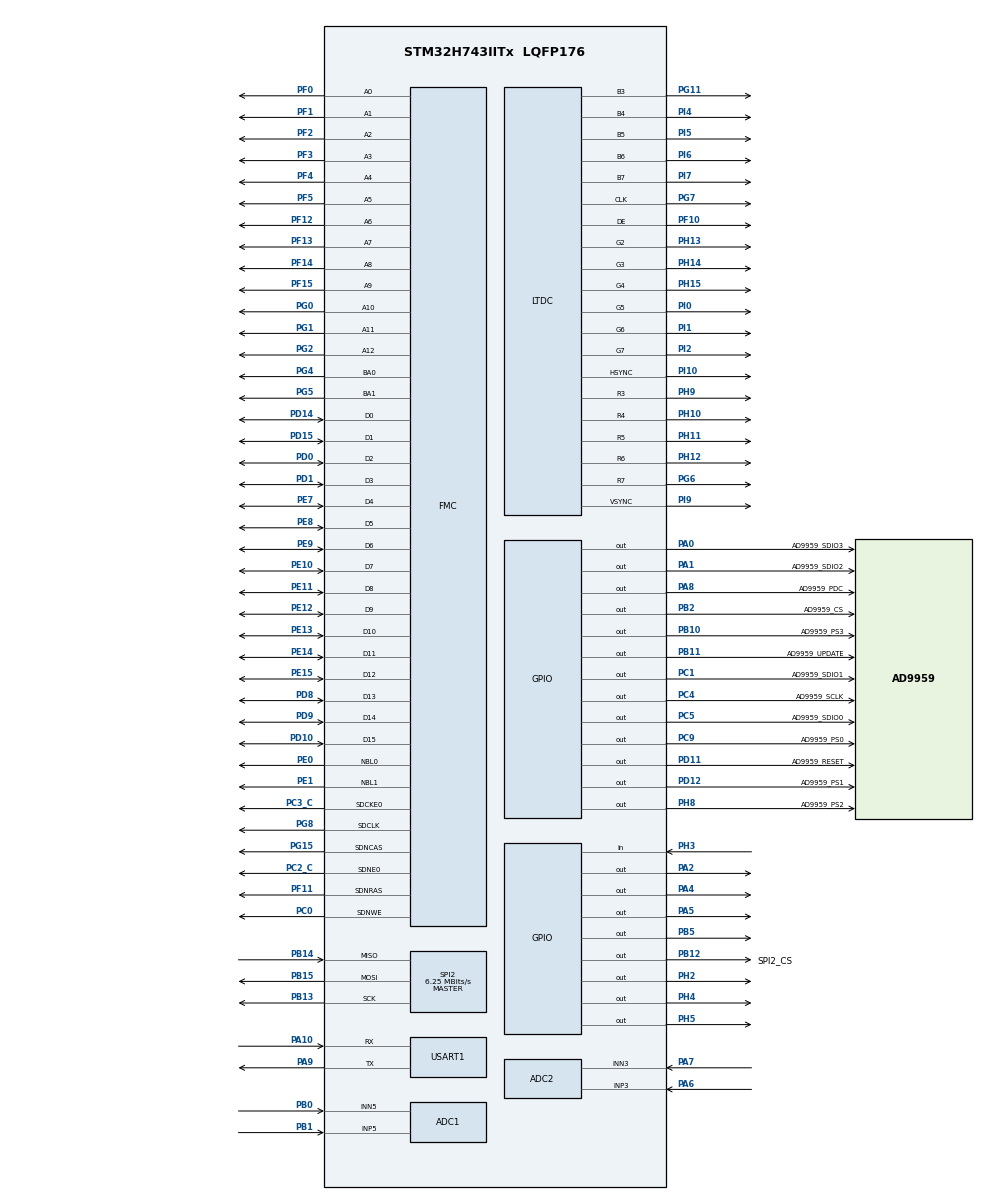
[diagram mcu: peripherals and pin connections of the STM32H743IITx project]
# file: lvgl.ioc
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ADC1.Channel-0\#ChannelRegularConversion=ADC_CHANNEL_5
ADC1.ClockPrescaler=ADC_CLOCK_ASYNC_DIV4
ADC1.ConversionDataManagement=ADC_CONVERSIONDATA_DMA_CIRCULAR
ADC1.DMAAccessModeView=ENABLE
ADC1.EOCSelection=ADC_EOC_SINGLE_CONV
ADC1.ExternalTrigConv=ADC_EXTERNALTRIG_T6_TRGO
ADC1.Mode=ADC_DUALMODE_REGSIMULT
ADC1.NbrOfConversion=1
ADC1.NbrOfConversionFlag=1
ADC1.OffsetNumber-0\#ChannelRegularConversion=ADC_OFFSET_NONE
ADC1.OffsetSignedSaturation-0\#ChannelRegularConversion=DISABLE
ADC1.Overrun=ADC_OVR_DATA_OVERWRITTEN
ADC1.Rank-0\#ChannelRegularConversion=1
ADC1.SamplingTime-0\#ChannelRegularConversion=ADC_SAMPLETIME_1CYCLE_5
ADC1.SingleDiff-0\#ChannelRegularConversion=ADC_DIFFERENTIAL_ENDED
ADC1.master=1
ADC2.Channel-0\#ChannelRegularConversion=ADC_CHANNEL_3
ADC2.ClockPrescaler=ADC_CLOCK_ASYNC_DIV4
ADC2.ConversionDataManagement=ADC_CONVERSIONDATA_DR
ADC2.DMAAccessModeView=ENABLE
ADC2.EOCSelection=ADC_EOC_SINGLE_CONV
ADC2.Mode=ADC_DUALMODE_REGSIMULT
ADC2.NbrOfConversionFlag=1
ADC2.OffsetNumber-0\#ChannelRegularConversion=ADC_OFFSET_NONE
ADC2.OffsetSignedSaturation-0\#ChannelRegularConversion=DISABLE
ADC2.Overrun=ADC_OVR_DATA_OVERWRITTEN
ADC2.Rank-0\#ChannelRegularConversion=1
ADC2.SamplingTime-0\#ChannelRegularConversion=ADC_SAMPLETIME_1CYCLE_5
ADC2.SingleDiff-0\#ChannelRegularConversion=ADC_DIFFERENTIAL_ENDED
DMA2D.ColorMode=DMA2D_OUTPUT_RGB565
DMA2D.Mode=DMA2D_R2M
Dma.ADC1.0.Direction=DMA_PERIPH_TO_MEMORY
Dma.ADC1.0.EventEnable=DISABLE
Dma.ADC1.0.FIFOMode=DMA_FIFOMODE_DISABLE
Dma.ADC1.0.Instance=DMA1_Stream0
Dma.ADC1.0.MemDataAlignment=DMA_MDATAALIGN_WORD
Dma.ADC1.0.MemInc=DMA_MINC_ENABLE
Dma.ADC1.0.Mode=DMA_NORMAL
Dma.ADC1.0.PeriphDataAlignment=DMA_PDATAALIGN_WORD
Dma.ADC1.0.PeriphInc=DMA_PINC_DISABLE
Dma.ADC1.0.Polarity=HAL_DMAMUX_REQ_GEN_RISING
Dma.ADC1.0.Priority=DMA_PRIORITY_LOW
Dma.ADC1.0.RequestNumber=1
Dma.ADC1.0.SignalID=NONE
Dma.ADC1.0.SyncEnable=DISABLE
Dma.ADC1.0.SyncPolarity=HAL_DMAMUX_SYNC_NO_EVENT
Dma.ADC1.0.SyncRequestNumber=1
Dma.ADC1.0.SyncSignalID=NONE
Dma.Request0=ADC1
Dma.Request1=SPI2_RX
Dma.Request2=SPI2_TX
Dma.SPI2_RX.1.Direction=DMA_PERIPH_TO_MEMORY
Dma.SPI2_RX.1.EventEnable=DISABLE
Dma.SPI2_RX.1.FIFOMode=DMA_FIFOMODE_DISABLE
Dma.SPI2_RX.1.Instance=DMA1_Stream3
Dma.SPI2_RX.1.MemDataAlignment=DMA_MDATAALIGN_WORD
Dma.SPI2_RX.1.MemInc=DMA_MINC_ENABLE
Dma.SPI2_RX.1.Mode=DMA_NORMAL
Dma.SPI2_RX.1.PeriphDataAlignment=DMA_PDATAALIGN_WORD
Dma.SPI2_RX.1.PeriphInc=DMA_PINC_DISABLE
Dma.SPI2_RX.1.Polarity=HAL_DMAMUX_REQ_GEN_RISING
Dma.SPI2_RX.1.Priority=DMA_PRIORITY_LOW
Dma.SPI2_RX.1.RequestNumber=1
Dma.SPI2_RX.1.SignalID=NONE
Dma.SPI2_RX.1.SyncEnable=DISABLE
Dma.SPI2_RX.1.SyncPolarity=HAL_DMAMUX_SYNC_NO_EVENT
Dma.SPI2_RX.1.SyncRequestNumber=1
Dma.SPI2_RX.1.SyncSignalID=NONE
Dma.SPI2_TX.2.Direction=DMA_MEMORY_TO_PERIPH
Dma.SPI2_TX.2.EventEnable=DISABLE
Dma.SPI2_TX.2.FIFOMode=DMA_FIFOMODE_DISABLE
Dma.SPI2_TX.2.Instance=DMA1_Stream4
Dma.SPI2_TX.2.MemDataAlignment=DMA_MDATAALIGN_WORD
Dma.SPI2_TX.2.MemInc=DMA_MINC_ENABLE
Dma.SPI2_TX.2.Mode=DMA_NORMAL
Dma.SPI2_TX.2.PeriphDataAlignment=DMA_PDATAALIGN_WORD
Dma.SPI2_TX.2.PeriphInc=DMA_PINC_DISABLE
Dma.SPI2_TX.2.Polarity=HAL_DMAMUX_REQ_GEN_RISING
Dma.SPI2_TX.2.Priority=DMA_PRIORITY_LOW
Dma.SPI2_TX.2.RequestNumber=1
Dma.SPI2_TX.2.SignalID=NONE
Dma.SPI2_TX.2.SyncEnable=DISABLE
Dma.SPI2_TX.2.SyncPolarity=HAL_DMAMUX_SYNC_NO_EVENT
Dma.SPI2_TX.2.SyncRequestNumber=1
Dma.SPI2_TX.2.SyncSignalID=NONE
FMC.CASLatency1=FMC_SDRAM_CAS_LATENCY_3
FMC.ColumnBitsNumber1=FMC_SDRAM_COLUMN_BITS_NUM_9
FMC.ExitSelfRefreshDelay1=8
FMC.LoadToActiveDelay1=2
FMC.RCDDelay1=6
FMC.RPDelay1=2
FMC.RPDelay2=2
FMC.ReadBurst1=FMC_SDRAM_RBURST_ENABLE
FMC.ReadBurst2=FMC_SDRAM_RBURST_ENABLE
FMC.ReadPipeDelay1=FMC_SDRAM_RPIPE_DELAY_1
FMC.ReadPipeDelay2=FMC_SDRAM_RPIPE_DELAY_1
FMC.RowCycleDelay1=6
FMC.RowCycleDelay2=6
FMC.SDClockPeriod1=FMC_SDRAM_CLOCK_PERIOD_2
FMC.SDClockPeriod2=FMC_SDRAM_CLOCK_PERIOD_2
FMC.SelfRefreshTime1=6
FMC.WriteRecoveryTime1=2
LTDC.ActiveH=600
LTDC.ActiveW=1024
LTDC.Alpha_L0=255
LTDC.FBStartAdress_L0=0xC0000000
LTDC.HBP=140
LTDC.HFP=160
LTDC.HSync=20
LTDC.ImageHeight_L0=600
LTDC.ImageWidth_L0=1024
LTDC.Layers=0
LTDC.PixelFormat_L0=LTDC_PIXEL_FORMAT_RGB565
LTDC.VBP=20
LTDC.VFP=12
LTDC.VSync=3
LTDC.WindowX1_L0=1024
LTDC.WindowY1_L0=600
Mcu.Family=STM32H7
Mcu.Name=STM32H743IITx
Mcu.Package=LQFP176
NVIC.ADC_IRQn=true\:0\:0\:false\:false\:true\:true\:true
NVIC.DMA1_Stream0_IRQn=true\:0\:0\:false\:false\:true\:false\:true
NVIC.DMA1_Stream3_IRQn=true\:0\:0\:false\:false\:true\:false\:true
NVIC.DMA1_Stream4_IRQn=true\:0\:0\:false\:false\:true\:false\:true
NVIC.PriorityGroup=NVIC_PRIORITYGROUP_4
NVIC.SPI2_IRQn=true\:0\:0\:false\:false\:true\:false\:true
NVIC.TIM2_IRQn=true\:0\:0\:false\:false\:true\:true\:true
PA0.GPIO_Label=AD9959_SDIO3
PA0.GPIO_PuPd=GPIO_PULLDOWN
PA0.Signal=GPIO_Output
PA1.GPIO_Label=AD9959_SDIO2
PA1.GPIO_PuPd=GPIO_PULLDOWN
PA1.Signal=GPIO_Output
PA10.Mode=Asynchronous
PA10.Signal=USART1_RX
PA2.GPIO_PuPd=GPIO_PULLDOWN
PA2.Signal=GPIO_Output
PA4.GPIO_PuPd=GPIO_PULLDOWN
PA4.Signal=GPIO_Output
PA5.GPIO_PuPd=GPIO_PULLDOWN
PA5.Signal=GPIO_Output
PA6.Signal=ADCx_INP3
PA7.Signal=ADCx_INN3
PA8.GPIO_Label=AD9959_PDC
PA8.GPIO_PuPd=GPIO_PULLDOWN
PA8.Signal=GPIO_Output
PA9.Mode=Asynchronous
PA9.Signal=USART1_TX
PB0.Signal=ADCx_INN5
PB1.Signal=ADCx_INP5
PB10.GPIO_Label=AD9959_PS3
PB10.GPIO_PuPd=GPIO_PULLDOWN
PB10.Signal=GPIO_Output
PB11.GPIO_Label=AD9959_UPDATE
PB11.GPIO_PuPd=GPIO_PULLDOWN
PB11.Signal=GPIO_Output
PB12.GPIO_Label=SPI2_CS
PB12.GPIO_PuPd=GPIO_PULLUP
PB12.GPIO_Speed=GPIO_SPEED_FREQ_HIGH
PB12.PinState=GPIO_PIN_SET
PB12.Signal=GPIO_Output
PB13.Mode=Full_Duplex_Master
PB13.Signal=SPI2_SCK
PB14.Mode=Full_Duplex_Master
PB14.Signal=SPI2_MISO
PB15.Mode=Full_Duplex_Master
PB15.Signal=SPI2_MOSI
PB2.GPIO_Label=AD9959_CS
PB2.GPIO_PuPd=GPIO_PULLUP
PB2.Signal=GPIO_Output
PB5.GPIO_PuPd=GPIO_PULLUP
PB5.Signal=GPIO_Output
PC0.Signal=FMC_SDNWE
PC1.GPIO_Label=AD9959_SDIO1
PC1.GPIO_PuPd=GPIO_PULLDOWN
PC1.Signal=GPIO_Output
PC14-OSC32_IN\ (OSC32_IN).Mode=LSE-External-Oscillator
PC14-OSC32_IN\ (OSC32_IN).Signal=RCC_OSC32_IN
PC15-OSC32_OUT\ (OSC32_OUT).Mode=LSE-External-Oscillator
PC15-OSC32_OUT\ (OSC32_OUT).Signal=RCC_OSC32_OUT
PC2_C.Mode=SdramChipSelect1_1
PC2_C.Signal=FMC_SDNE0
PC3_C.Mode=SdramChipSelect1_1
PC3_C.Signal=FMC_SDCKE0
PC4.GPIO_Label=AD9959_SCLK
PC4.GPIO_PuPd=GPIO_PULLDOWN
PC4.Signal=GPIO_Output
PC5.GPIO_Label=AD9959_SDIO0
PC5.GPIO_PuPd=GPIO_PULLDOWN
PC5.Signal=GPIO_Output
PC9.GPIO_Label=AD9959_PS0
PC9.GPIO_PuPd=GPIO_PULLDOWN
PC9.Signal=GPIO_Output
PD0.Signal=FMC_D2_DA2
PD1.Signal=FMC_D3_DA3
PD10.Signal=FMC_D15_DA15
PD11.GPIO_Label=AD9959_RESET
PD11.GPIO_PuPd=GPIO_PULLDOWN
PD11.Signal=GPIO_Output
PD12.GPIO_Label=AD9959_PS1
PD12.GPIO_PuPd=GPIO_PULLDOWN
PD12.Signal=GPIO_Output
PD14.Signal=FMC_D0_DA0
PD15.Signal=FMC_D1_DA1
PD7.Signal=FMC_NE1
PD8.Signal=FMC_D13_DA13
PD9.Signal=FMC_D14_DA14
PE0.Signal=FMC_NBL0
PE1.Signal=FMC_NBL1
PE10.Signal=FMC_D7_DA7
PE11.Signal=FMC_D8_DA8
PE12.Signal=FMC_D9_DA9
PE13.Signal=FMC_D10_DA10
PE14.Signal=FMC_D11_DA11
PE15.Signal=FMC_D12_DA12
PE7.Signal=FMC_D4_DA4
PE8.Signal=FMC_D5_DA5
PE9.Signal=FMC_D6_DA6
PF0.Signal=FMC_A0
PF1.Signal=FMC_A1
PF10.GPIO_Speed=GPIO_SPEED_FREQ_HIGH
PF10.Mode=RGB565
PF10.Signal=LTDC_DE
PF11.Signal=FMC_SDNRAS
PF12.Signal=FMC_A6
PF13.Signal=FMC_A7
PF14.Signal=FMC_A8
PF15.Signal=FMC_A9
PF2.Signal=FMC_A2
PF3.Signal=FMC_A3
PF4.Signal=FMC_A4
PF5.Signal=FMC_A5
PG0.Signal=FMC_A10
PG1.Signal=FMC_A11
PG11.GPIO_Speed=GPIO_SPEED_FREQ_HIGH
PG11.Mode=RGB565
PG11.Signal=LTDC_B3
PG15.Signal=FMC_SDNCAS
PG2.Signal=FMC_A12
PG4.Signal=FMC_A14_BA0
PG5.Signal=FMC_A15_BA1
PG6.GPIO_Speed=GPIO_SPEED_FREQ_HIGH
PG6.Mode=RGB565
PG6.Signal=LTDC_R7
PG7.GPIO_Speed=GPIO_SPEED_FREQ_HIGH
PG7.Mode=RGB565
PG7.Signal=LTDC_CLK
PG8.Signal=FMC_SDCLK
PH0-OSC_IN\ (PH0).Mode=HSE-External-Oscillator
PH0-OSC_IN\ (PH0).Signal=RCC_OSC_IN
PH1-OSC_OUT\ (PH1).Mode=HSE-External-Oscillator
PH1-OSC_OUT\ (PH1).Signal=RCC_OSC_OUT
PH10.GPIO_Speed=GPIO_SPEED_FREQ_HIGH
PH10.Mode=RGB565
PH10.Signal=LTDC_R4
PH11.GPIO_Speed=GPIO_SPEED_FREQ_HIGH
PH11.Mode=RGB565
PH11.Signal=LTDC_R5
PH12.GPIO_Speed=GPIO_SPEED_FREQ_HIGH
PH12.Mode=RGB565
PH12.Signal=LTDC_R6
PH13.GPIO_Speed=GPIO_SPEED_FREQ_HIGH
PH13.Mode=RGB565
PH13.Signal=LTDC_G2
PH14.GPIO_Speed=GPIO_SPEED_FREQ_HIGH
PH14.Mode=RGB565
PH14.Signal=LTDC_G3
PH15.GPIO_Speed=GPIO_SPEED_FREQ_HIGH
PH15.Mode=RGB565
PH15.Signal=LTDC_G4
PH2.GPIO_PuPd=GPIO_PULLDOWN
PH2.Signal=GPIO_Output
PH3.GPIO_PuPd=GPIO_PULLDOWN
PH3.Signal=GPIO_Input
PH4.GPIO_PuPd=GPIO_PULLDOWN
PH4.Signal=GPIO_Output
PH5.Signal=GPIO_Output
PH8.GPIO_Label=AD9959_PS2
PH8.GPIO_PuPd=GPIO_PULLDOWN
PH8.Signal=GPIO_Output
PH9.GPIO_Speed=GPIO_SPEED_FREQ_HIGH
PH9.Mode=RGB565
PH9.Signal=LTDC_R3
PI0.GPIO_Speed=GPIO_SPEED_FREQ_HIGH
PI0.Mode=RGB565
PI0.Signal=LTDC_G5
PI1.GPIO_Speed=GPIO_SPEED_FREQ_HIGH
PI1.Mode=RGB565
PI1.Signal=LTDC_G6
PI10.GPIO_Speed=GPIO_SPEED_FREQ_HIGH
PI10.Mode=RGB565
PI10.Signal=LTDC_HSYNC
PI2.GPIO_Speed=GPIO_SPEED_FREQ_HIGH
PI2.Mode=RGB565
PI2.Signal=LTDC_G7
PI4.GPIO_Speed=GPIO_SPEED_FREQ_HIGH
PI4.Mode=RGB565
PI4.Signal=LTDC_B4
PI5.GPIO_Speed=GPIO_SPEED_FREQ_HIGH
PI5.Mode=RGB565
PI5.Signal=LTDC_B5
PI6.GPIO_Speed=GPIO_SPEED_FREQ_HIGH
PI6.Mode=RGB565
PI6.Signal=LTDC_B6
PI7.GPIO_Speed=GPIO_SPEED_FREQ_HIGH
PI7.Mode=RGB565
PI7.Signal=LTDC_B7
PI9.GPIO_Speed=GPIO_SPEED_FREQ_HIGH
PI9.Mode=RGB565
PI9.Signal=LTDC_VSYNC
ProjectManager.HeapSize=0x2000
ProjectManager.StackSize=0x2000
ProjectManager.TargetToolchain=STM32CubeIDE
RCC.ADCFreq_Value=50000000
RCC.APB1Freq_Value=120000000
RCC.APB2Freq_Value=120000000
RCC.APB3Freq_Value=120000000
RCC.APB4Freq_Value=120000000
RCC.CortexFreq_Value=480000000
RCC.D1PPRE=RCC_APB3_DIV2
RCC.D2PPRE1=RCC_APB1_DIV2
RCC.D2PPRE2=RCC_APB2_DIV2
RCC.D3PPRE=RCC_APB4_DIV2
RCC.DIVM1=5
RCC.DIVM2=2
RCC.DIVM3=1
RCC.DIVN1=192
RCC.DIVN2=12
RCC.DIVN3=6
RCC.DIVP2=3
RCC.DIVR3=3
RCC.HCLKFreq_Value=240000000
RCC.HPRE=RCC_HCLK_DIV2
RCC.PLL2FRACN=0
RCC.PLL3FRACN=0
RCC.PLLFRACN=0
RCC.PLLSourceVirtual=RCC_PLLSOURCE_HSE
RCC.PWR_Regulator_Voltage_Scale=PWR_REGULATOR_VOLTAGE_SCALE0
RCC.SPI123CLockSelection=RCC_SPI123CLKSOURCE_PLL2
RCC.SYSCLKFreq_VALUE=480000000
RCC.SYSCLKSource=RCC_SYSCLKSOURCE_PLLCLK
RCC.USBFreq_Value=480000000
SH.ADCx_INN3.0=ADC2_INN3,IN3-Differential
SH.ADCx_INN5.0=ADC1_INN5,IN5-Differential
SH.ADCx_INP3.0=ADC2_INP3,IN3-Differential
SH.ADCx_INP5.0=ADC1_INP5,IN5-Differential
SH.FMC_A0.0=FMC_A0,13b-sda1
SH.FMC_A1.0=FMC_A1,13b-sda1
SH.FMC_A10.0=FMC_A10,13b-sda1
SH.FMC_A11.0=FMC_A11,13b-sda1
SH.FMC_A12.0=FMC_A12,13b-sda1
SH.FMC_A14_BA0.0=FMC_BA0,FourSdramBanks1
SH.FMC_A15_BA1.0=FMC_BA1,FourSdramBanks1
SH.FMC_A2.0=FMC_A2,13b-sda1
SH.FMC_A3.0=FMC_A3,13b-sda1
SH.FMC_A4.0=FMC_A4,13b-sda1
SH.FMC_A5.0=FMC_A5,13b-sda1
SH.FMC_A6.0=FMC_A6,13b-sda1
SH.FMC_A7.0=FMC_A7,13b-sda1
SH.FMC_A8.0=FMC_A8,13b-sda1
SH.FMC_A9.0=FMC_A9,13b-sda1
SH.FMC_D0_DA0.0=FMC_D0,sd-16b-d1
SH.FMC_D10_DA10.0=FMC_D10,sd-16b-d1
SH.FMC_D11_DA11.0=FMC_D11,sd-16b-d1
SH.FMC_D12_DA12.0=FMC_D12,sd-16b-d1
SH.FMC_D13_DA13.0=FMC_D13,sd-16b-d1
SH.FMC_D14_DA14.0=FMC_D14,sd-16b-d1
SH.FMC_D15_DA15.0=FMC_D15,sd-16b-d1
SH.FMC_D1_DA1.0=FMC_D1,sd-16b-d1
SH.FMC_D2_DA2.0=FMC_D2,sd-16b-d1
SH.FMC_D3_DA3.0=FMC_D3,sd-16b-d1
SH.FMC_D4_DA4.0=FMC_D4,sd-16b-d1
SH.FMC_D5_DA5.0=FMC_D5,sd-16b-d1
SH.FMC_D6_DA6.0=FMC_D6,sd-16b-d1
SH.FMC_D7_DA7.0=FMC_D7,sd-16b-d1
SH.FMC_D8_DA8.0=FMC_D8,sd-16b-d1
SH.FMC_D9_DA9.0=FMC_D9,sd-16b-d1
SH.FMC_NBL0.0=FMC_NBL0,Sd2ByteEnable1
SH.FMC_NBL1.0=FMC_NBL1,Sd2ByteEnable1
SH.FMC_SDCLK.0=FMC_SDCLK,13b-sda1
SH.FMC_SDNCAS.0=FMC_SDNCAS,13b-sda1
SH.FMC_SDNRAS.0=FMC_SDNRAS,13b-sda1
SH.FMC_SDNWE.0=FMC_SDNWE,13b-sda1
SPI2.BaudRatePrescaler=SPI_BAUDRATEPRESCALER_8
SPI2.CLKPhase=SPI_PHASE_2EDGE
SPI2.CalculateBaudRate=6.25 MBits/s
SPI2.DataSize=SPI_DATASIZE_32BIT
SPI2.Direction=SPI_DIRECTION_2LINES
SPI2.Mode=SPI_MODE_MASTER
SPI2.VirtualType=VM_MASTER
STMicroelectronics.X-CUBE-ALGOBUILD.1.3.0.LibraryCcDSPOoLibraryJjDSPOoLibrary=true
TIM2.Period=599
TIM2.Prescaler=399
TIM5.AutoReloadPreload=TIM_AUTORELOAD_PRELOAD_ENABLE
TIM5.Period=999
TIM5.Prescaler=239
TIM5.TIM_MasterOutputTrigger=TIM_TRGO_UPDATE
TIM6.AutoReloadPreload=TIM_AUTORELOAD_PRELOAD_ENABLE
TIM6.Period=74
TIM6.Prescaler=24
TIM6.TIM_MasterOutputTrigger=TIM_TRGO_UPDATE
TIM7.AutoReloadPreload=TIM_AUTORELOAD_PRELOAD_ENABLE
TIM7.Period=9
TIM7.Prescaler=23
TIM7.TIM_MasterOutputTrigger=TIM_TRGO_UPDATE
USART1.VirtualMode-Asynchronous=VM_ASYNC
VP_DMA2D_VS_DMA2D.Mode=DMA2D_Activate
VP_STMicroelectronics.X-CUBE-ALGOBUILD_VS_DSPOoLibraryJjLibrary_1.3.0_1.3.0.Mode=DSPOoLibraryJjLibrary
VP_TIM2_VS_ClockSourceINT.Mode=Internal
VP_TIM5_VS_ClockSourceINT.Mode=Internal
VP_TIM6_VS_ClockSourceINT.Mode=Enable_Timer
VP_TIM7_VS_ClockSourceINT.Mode=Enable_Timer
board=custom

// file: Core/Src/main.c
/* USER CODE BEGIN Header */
/**
  ******************************************************************************
  * @file           : main.c
  * @brief          : Main program body
  ******************************************************************************
  * @attention
  *
  * <h2><center>&copy; Copyright (c) 2022 STMicroelectronics.
  * All rights reserved.</center></h2>
  *
  * This software component is licensed by ST under BSD 3-Clause license,
  * the "License"; You may not use this file except in compliance with the
  * License. You may obtain a copy of the License at:
  *                        opensource.org/licenses/BSD-3-Clause
  *
  ******************************************************************************
  */
/* USER CODE END Header */
#include "main.h"
#include "adc.h"
#include "dma.h"
#include "dma2d.h"
#include "ltdc.h"
#include "spi.h"
#include "tim.h"
#include "usart.h"
#include "gpio.h"
#include "fmc.h"

/* USER CODE BEGIN Includes */
#include "touch.h"
#include "lcd_rgb_ltdc_drv.h"
#include "lvgl.h"
#include "lv_port_indev.h"
#include "lv_port_disp.h"
#include "retarget.h"
#include "gui_guider.h"
#include "arm_math.h"
#include "arm_const_structs.h"
#include "ad9959.h"
#include "my_lib.h"
#include "PID.h"
//#include "ad9910.h"
#define Vref1 3.598
#define Vref2 3.599
#define FFT_LENGTH 1024
#define sin 1;
#define tri 2;
/* USER CODE END Includes */

/* USER CODE BEGIN PTD */
lv_ui guider_ui;
/* USER CODE END PTD */

/* USER CODE BEGIN PM */
uint32_t data_out[6]={1073741824,1073741824,0,0,8589935,1717987},spi_data_in[1024],spi_data_out[1024]={0};
uint16_t spi_flag = 0,start_flag1 = 0,start_flag2 = 0,start_flag3 = 0,set_phase = 0,amp_flag = 0;
uint32_t data_in[2047];
uint32_t Fs=640000;
float data_in1[2047],data_in2[2047];
//double Phase=0,Phase1=0,Phase2=0,Amp1,Amp2;
uint16_t flag=1,mode=1;
//extern uint16_t flag0;
//float u[5]={0};
float fft_inputbuf[FFT_LENGTH * 2];
float fft_outputbuf[FFT_LENGTH];
PID_TypeDef mypid1;
PID_TypeDef mypid2;
/* USER CODE END PM */

/* USER CODE BEGIN PV */

void ADC_Start(void)
{
    flag = 1;
    HAL_ADCEx_MultiModeStart_DMA(&hadc1,(uint32_t*)data_in,2047);
    while(flag);
    for(int i = 0;i < 2047;i++)
    {
        data_in1[i] = (((data_in[i] >> 16) * 2.0 / 65535.0-1.0) * Vref1 - 0.138);
        data_in2[i] = (((data_in[i] & 0xffff) * 2.0 / 65535.0-1.0) * Vref2 - 0.14);
//          if(Vmax1 < data_in1[i]) Vmax1 = data_in1[i];
//          if(Vmin1 > data_in1[i]) Vmin1 = data_in1[i];
//        printf("%lf,%lf,%d\r\n",data_in1[i],data_in2[i],i);
    }
}

Get_Amp(double* amp,uint16_t * loc,uint16_t* num)
{
    uint16_t Num = 1;
    for(int i = 1;i < FFT_LENGTH/2;i++)
        if(fft_outputbuf[i] > 0.1) {amp[0] = fft_outputbuf[i];loc[0] = i; ;break; }
    for(int i = loc[0]+1;i < FFT_LENGTH/2;i++) {
        if (fft_outputbuf[i] > 0.01) {
            amp[Num] = fft_outputbuf[i];
            loc[Num] = i;
//            printf("amp=%lf,%d,%d\r\n",amp[Num],loc[Num],i);
            Num++;
        }
    }
    *num = Num - 1;
}

Judge_wave(double* amp,uint16_t* num,uint16_t* wave1,uint16_t* wave2)
{
    double max=0;
    if(*num == 1) {*wave1 = sin;*wave2 = sin;}
    else if(*num > 1)
    {
        if(amp[0] > 0.46) {*wave1 = sin;*wave2 = tri;}
        else if(amp[0] < 0.46)
        {
            for(int i = 1;i <= *num;i++)
                if(amp[i] > max) max = amp[i];
            if(max > 0.43) {*wave1 = tri;*wave2 = sin;}
            else {*wave1 = tri;*wave2 = tri;}
        }
    }
}

Get_fre(double* amp,uint16_t * loc,uint16_t* num,uint16_t* wave1,uint16_t* wave2,double* Fre1,double* Fre2,double * phase1,double * phase2)
{
    double max=0;
    uint16_t max1,max2;
    uint16_t Location;
    for(int i = 1;i <= *num;i++)
    {
        if(amp[i] > max) {max = amp[i];Location=i;}
    }
    *Fre2 = *Fre1 * loc[Location] * 1.0 / loc[0];
    max1 = *Fre1 / 625;
    if(fft_inputbuf[max1*2+1] >= 0 && fft_inputbuf[max1*2] >= 0)
        *phase1 = atan(fft_inputbuf[max1*2+1] / fft_inputbuf[max1*2]) / PI * 180;
    else if(fft_inputbuf[max1*2+1] >= 0 && fft_inputbuf[max1*2] <= 0)
        *phase1 = atan(fft_inputbuf[max1*2+1] / fft_inputbuf[max1*2]) / PI * 180 + 180;
    else if(fft_inputbuf[max1*2+1] <= 0 && fft_inputbuf[max1*2] <= 0)
        *phase1 = atan(fft_inputbuf[max1*2+1] / fft_inputbuf[max1*2]) / PI * 180 + 180;
    else if(fft_inputbuf[max1*2+1] <= 0 && fft_inputbuf[max1*2] >= 0)
        *phase1 = atan(fft_inputbuf[max1*2+1] / fft_inputbuf[max1*2]) / PI * 180 + 360;
    max2 = *Fre2 / 625;
    if(fft_inputbuf[max2*2+1] >= 0 && fft_inputbuf[max2*2] >= 0)
        *phase2 = atan(fft_inputbuf[max2*2+1] / fft_inputbuf[max2*2]) / PI * 180;
    else if(fft_inputbuf[max2*2+1] >= 0 && fft_inputbuf[max2*2] <= 0)
        *phase2 = atan(fft_inputbuf[max2*2+1] / fft_inputbuf[max2*2]) / PI * 180 + 180;
    else if(fft_inputbuf[max2*2+1] <= 0 && fft_inputbuf[max2*2] <= 0)
        *phase2 = atan(fft_inputbuf[max2*2+1] / fft_inputbuf[max2*2]) / PI * 180 + 180;
    else if(fft_inputbuf[max2*2+1] <= 0 && fft_inputbuf[max2*2] >= 0)
        *phase2 = atan(fft_inputbuf[max2*2+1] / fft_inputbuf[max2*2]) / PI * 180 + 360;
//    printf("Location=%d\r\n",Location);
}

void FFT1(double * fre)
{
    uint16_t i,max1,max2,mode = 0;
    for(i=0;i<FFT_LENGTH;i++)
    {
        fft_inputbuf[i * 2]=data_in1[i];
        fft_inputbuf[i * 2 + 1] = 0;
//        printf("%.2lf\r\n",fft_inputbuf[i*2]);
    }
    arm_cfft_f32(&arm_cfft_sR_f32_len1024, fft_inputbuf, 0, 1);
    arm_cmplx_mag_f32(fft_inputbuf, fft_outputbuf, FFT_LENGTH);
    fft_outputbuf[0] /= FFT_LENGTH;
    mode=0;
    for (i = 1; i < FFT_LENGTH/2; i++)
    {
        fft_outputbuf[i] /= FFT_LENGTH/2;
        if(fft_outputbuf[i] < 0.006) fft_outputbuf[i] = 0;
//        printf("%lf,%d\r\n",fft_outputbuf[i],i);
    }
    for (i = 1; i < FFT_LENGTH/2; i++)
    {
        if(fft_outputbuf[i] > 0.1 && !mode)
        {
            max1 = i;mode=1;break;
        }
    }
    mode = 0;
    for (i = max1+1; i < FFT_LENGTH/2; i++)
    {
        if(fft_outputbuf[i] > 0.1 && !mode)
        {
            max2 = i;mode=1;break;
        }
    }
    *fre = 625*max1;
}

void FFT2(double* fre1,double* fre2)
{
    uint16_t i,max1,max2,mode = 0;
    double max_1,max_2;
    for(i=0;i<FFT_LENGTH;i++)
    {
        fft_inputbuf[i * 2]=spi_data_in[i];
        fft_inputbuf[i * 2 + 1] = 0;
//        printf("%.2lf\r\n",fft_inputbuf[i*2]);
    }
    arm_cfft_f32(&arm_cfft_sR_f32_len1024, fft_inputbuf, 0, 1);
    arm_cmplx_mag_f32(fft_inputbuf, fft_outputbuf, FFT_LENGTH);
    fft_outputbuf[0] /= FFT_LENGTH;
    mode=0;
    for (i = 1; i < FFT_LENGTH/2; i++)
    {
        fft_outputbuf[i] /= FFT_LENGTH/2;
        if(fft_outputbuf[i] < 0.006) fft_outputbuf[i] = 0;
//        printf("%lf,%d\r\n",fft_outputbuf[i],i);
    }
    for (i = 1; i < FFT_LENGTH/2; i++)
    {
        if(fft_outputbuf[i] > 100 && !mode)
        {
            max1 = i;mode=1;break;
        }
    }
    mode = 0;
    for (i = max1+2; i < FFT_LENGTH/2; i++)
    {
        if(fft_outputbuf[i] > 100 && !mode)
        {
            max2 = i;mode=1;break;
        }
    }
    if(fft_outputbuf[max1+1] > 0.001 || fft_outputbuf[max1-1] > 0.001)
    {
        if(fft_outputbuf[max1+1]>=fft_outputbuf[max1-1])
        {max_1=max1+fft_outputbuf[max1+1]*1.0/(fft_outputbuf[max1+1]+fft_outputbuf[max1]);}
        else
        {max_1=max1-fft_outputbuf[max1-1]*1.0/(fft_outputbuf[max1-1]+fft_outputbuf[max1]);}
    }
    if(fft_outputbuf[max2+1] > 0.001 || fft_outputbuf[max2-1] > 0.001)
    {
        if(fft_outputbuf[max2+1]>=fft_outputbuf[max2-1])
        {max_2=max2+fft_outputbuf[max2+1]*1.0/(fft_outputbuf[max2+1]+fft_outputbuf[max2]);}
        else
        {max_2=max2-fft_outputbuf[max2-1]*1.0/(fft_outputbuf[max2-1]+fft_outputbuf[max2]);}
    }
    *fre1 = round(48828.125 * max_1 / 50000) * 50000;
    *fre2 = round(48828.125 * max_2 / 50000) * 50000;
    if(*fre1 < 0) *fre1 = 0;
    if(*fre2 < 0) *fre2 = 0;
//    printf("max1=%d,max_1=%lf,max2=%d,max_2=%lf\r\n",max1,max_1,max2,max_2);
}

void FFT3(double* fre1,double* fre2)
{
    uint16_t i,max1,max2,mode = 0;
    double max_1,max_2;
    for(i=0;i<FFT_LENGTH;i++)
    {
        fft_inputbuf[i * 2]=data_in1[i];
        fft_inputbuf[i * 2 + 1] = 0;
//        printf("%.2lf\r\n",fft_inputbuf[i*2]);
    }
    arm_cfft_f32(&arm_cfft_sR_f32_len1024, fft_inputbuf, 0, 1);
    arm_cmplx_mag_f32(fft_inputbuf, fft_outputbuf, FFT_LENGTH);
    fft_outputbuf[0] /= FFT_LENGTH;
    mode=0;
    for (i = 1; i < FFT_LENGTH/2; i++)
    {
        fft_outputbuf[i] /= FFT_LENGTH/2;
        if(fft_outputbuf[i] < 0.006) fft_outputbuf[i] = 0;
//        printf("%lf,%d\r\n",fft_outputbuf[i],i);
    }
    for (i = 1; i < FFT_LENGTH/2; i++)
    {
        if(fft_outputbuf[i] > 0.2 && !mode)
        {
            max1 = i;mode=1;break;
        }
    }
    mode = 0;
    for (i = max1+4; i < FFT_LENGTH/2; i++)
    {
        if(fft_outputbuf[i] > 0.2 && !mode)
        {
            max2 = i;mode=1;break;
        }
    }
    if(fft_outputbuf[max1+1] > 0.001 || fft_outputbuf[max1-1] > 0.001)
    {
        if(fft_outputbuf[max1+1]>=fft_outputbuf[max1-1])
        {max_1=max1+fft_outputbuf[max1+1]*1.0/(fft_outputbuf[max1+1]+fft_outputbuf[max1]);}
        else
        {max_1=max1-fft_outputbuf[max1-1]*1.0/(fft_outputbuf[max1-1]+fft_outputbuf[max1]);}
    }
    else max_1 = max1;
    if(fft_outputbuf[max2+1] > 0.001 || fft_outputbuf[max2-1] > 0.001)
    {
        if(fft_outputbuf[max2+1]>=fft_outputbuf[max2-1])
        {max_2=max2+fft_outputbuf[max2+1]*1.0/(fft_outputbuf[max2+1]+fft_outputbuf[max2]);}
        else
        {max_2=max2-fft_outputbuf[max2-1]*1.0/(fft_outputbuf[max2-1]+fft_outputbuf[max2]);}
    }
    else max_2 = max2;
    *fre1 = round(246.71 * max_1 / 1000) * 1000;
    *fre2 = round(246.71 * max_2 / 1000) * 1000;
    if(*fre1 < 0) *fre1 = 0;
    if(*fre2 < 0) *fre2 = 0;
//    printf("max1=%d,max_1=%lf,max2=%d,max_2=%lf\r\n",max1,max_1,max2,max_2);
}

void SPI_1(uint16_t* wave1,uint16_t* wave2)
{
    HAL_GPIO_WritePin(GPIOB,GPIO_PIN_12,0);
    spi_flag = 0;
    HAL_SPI_Transmit_DMA(&hspi2, data_out,6);
    while (!spi_flag) {}
    HAL_GPIO_WritePin(GPIOB, GPIO_PIN_12, 1);
    if(*wave1 == 1) HAL_GPIO_WritePin(GPIOH, GPIO_PIN_2,0);
    else if(*wave1 == 2) HAL_GPIO_WritePin(GPIOH, GPIO_PIN_2,1);
    if(*wave2 == 1) HAL_GPIO_WritePin(GPIOA, GPIO_PIN_2,0);
    else if(*wave2 == 2) HAL_GPIO_WritePin(GPIOA, GPIO_PIN_2,1);
}

void SPI_2(void)
{
    HAL_GPIO_WritePin(GPIOB,GPIO_PIN_12,0);
    spi_flag = 0;
    HAL_SPI_TransmitReceive_DMA(&hspi2,spi_data_out,spi_data_in,1024);
    while (!spi_flag) {}
    HAL_GPIO_WritePin(GPIOB, GPIO_PIN_12, 1);
}

//void change_wave(uint16_t* wave1,uint16_t* wave2)
//{
//    if(*wave1 == 1) HAL_GPIO_WritePin(GPIOH,GPIO_PIN_3,1);
//    else if(*wave1 == 2) HAL_GPIO_WritePin(GPIOH,GPIO_PIN_3,0);
//    if(*wave2 == 1) HAL_GPIO_WritePin(GPIOA,GPIO_PIN_5,1);
//    else if(*wave2 == 2) HAL_GPIO_WritePin(GPIOA,GPIO_PIN_5,0);
//}

void show_data(double fre1,double fre2,uint16_t* wave1,uint16_t* wave2)
{
    double Vpp;
    char FRE1[10]="",FRE2[10]="",WAVE1[10]="",WAVE2[10]="";
    sprintf(FRE1,"%.0lfHz",fre1);
    sprintf(FRE2,"%.0lfHz",fre2);
    if(*wave1 == 1) sprintf(WAVE1,"sin");
    else if(*wave1 == 2) sprintf(WAVE1,"triangle");
    if(*wave2 == 1) sprintf(WAVE2,"sin");
    else if(*wave2 == 2) sprintf(WAVE2,"triangle");
    lv_label_set_text(guider_ui.screen_label_10, FRE1);
    lv_label_set_text(guider_ui.screen_label_11, FRE2);
    lv_label_set_text(guider_ui.screen_label_12, WAVE1);
    lv_label_set_text(guider_ui.screen_label_13, WAVE2);
    return;
}

/* USER CODE END PV */

void SystemClock_Config(void);
void PeriphCommonClock_Config(void);

int main(void)
{
  /* USER CODE BEGIN 1 */
    static uint16_t LCD_BUFFER[600][1024] __attribute__((section(".malloc")));
    double amp[512]={0},Fre1,Fre2,fre1,fre2,phase1,phase2,phase3,phase4,dphase1,dphase2,dphase;
    uint16_t num,wave1,wave2,loc[512]={0},mode=0;
  /* USER CODE END 1 */

  /* MCU Configuration--------------------------------------------------------*/

  /* Reset of all peripherals, Initializes the Flash interface and the Systick. */
  HAL_Init();

  /* Configure the system clock */
  SystemClock_Config();

/* Configure the peripherals common clocks */
  PeriphCommonClock_Config();

  /* USER CODE BEGIN SysInit */
  RetargetInit(&huart1);
  /* USER CODE END SysInit */

  /* Initialize all configured peripherals */
  MX_GPIO_Init();
  MX_FMC_Init();
  MX_DMA2D_Init();
  MX_LTDC_Init();
  MX_TIM6_Init();
  MX_DMA_Init();
  MX_ADC1_Init();
  MX_USART1_UART_Init();
  MX_TIM2_Init();
  MX_TIM5_Init();
  MX_TIM7_Init();
  MX_ADC2_Init();
  MX_SPI2_Init();
  /* USER CODE BEGIN 2 */
  LTDC_Init();
  tp_dev.init();
  HAL_GPIO_WritePin(GPIOB,GPIO_PIN_5,GPIO_PIN_SET);
  HAL_TIM_Base_Start_IT(&htim2);
  TIM6->ARR = 14;
  HAL_TIM_Base_Start(&htim6);
  HAL_TIM_Base_Start(&htim7);
  HAL_ADCEx_Calibration_Start(&hadc1, ADC_CALIB_OFFSET_LINEARITY, ADC_SINGLE_ENDED);
  lv_init();
  lv_port_disp_init();
  lv_port_indev_init();
  setup_ui(&guider_ui);
  /* USER CODE END 2 */

  /* Infinite loop */
  /* USER CODE BEGIN WHILE */
  while (1)
  {
      lv_task_handler();
      if(start_flag1) {
          HAL_TIM_Base_Stop(&htim6);
          TIM6->ARR = 14;
          HAL_TIM_Base_Start(&htim6);
          if(amp_flag) HAL_GPIO_WritePin(GPIOH,GPIO_PIN_5,1);
          else HAL_GPIO_WritePin(GPIOH,GPIO_PIN_5,0);
          HAL_GPIO_WritePin(GPIOH,GPIO_PIN_4,0);
          HAL_GPIO_WritePin(GPIOA,GPIO_PIN_5,0);
          ADC_Start();
          FFT1(&fre1);
          Get_Amp(amp, loc, &num);
          Judge_wave(amp, &num, &wave1, &wave2);
          Get_fre(amp, loc, &num, &wave1, &wave2, &fre1, &fre2, &phase1, &phase2);
          dphase = 0;
          if(wave1 == 1 && wave2 == 1 && mod(fre2,fre1) == 0)
          {
              mode = fre2 / fre1;
              apfft_phase(data_in1,mode,640000,fre1,&dphase);
              dphase = mod((dphase + 360), 360) >= 180 ? mod((dphase + 360), 360) - 360 : mod(
                      (dphase + 360), 360);
//              printf("dphase=%lf\r\n",dphase);
          }
          data_out[2] = ((360 - set_phase + dphase - 1 * (fre2/fre1/2)) * 11930464.71) / (fre2 / fre1);
//          printf("set_phase=%d,dphase=%lf,data_out=%lf\r\n",set_phase,dphase,data_out[2]);
          data_out[4] = 85.899 * fre1;
          data_out[5] = 85.899 * fre2;
          SPI_1(&wave1,&wave2);
//          printf("fre1=%lf,fre2=%lf,wave1=%d,wave2=%d\r\n",fre1,fre2,wave1,wave2);
          show_data(fre1, fre2, &wave1, &wave2);
      }
      else if(start_flag2)
      {
          HAL_GPIO_WritePin(GPIOH,GPIO_PIN_5,0);
          HAL_GPIO_WritePin(GPIOH,GPIO_PIN_4,1);
          HAL_GPIO_WritePin(GPIOA,GPIO_PIN_5,0);
          HAL_GPIO_WritePin(GPIOH, GPIO_PIN_2,0);
          HAL_GPIO_WritePin(GPIOA, GPIO_PIN_2,0);
          if(HAL_GPIO_ReadPin(GPIOH,GPIO_PIN_3)) {
              SPI_2();
//              printf("123\r\n");
//              for(int i = 0;i < 1024;i++)
//                  printf("%d,%d\r\n",spi_data_in[i],i);
          }
          FFT2(&fre1,&fre2);
          spi_data_out[0] = fre1 * 85.899;
          spi_data_out[1] = fre2 * 85.899;
//          printf("fre1=%lf,fre2=%lf\r\n",fre1,fre2);
      }
      else if(start_flag3)
      {
          HAL_TIM_Base_Stop(&htim6);
          TIM6->ARR = 37;
          HAL_TIM_Base_Start(&htim6);
          HAL_GPIO_WritePin(GPIOH,GPIO_PIN_5,0);
          HAL_GPIO_WritePin(GPIOH,GPIO_PIN_4,0);
          HAL_GPIO_WritePin(GPIOA,GPIO_PIN_5,0);
          ADC_Start();
          FFT3(&fre1,&fre2);
          data_out[4] = 85.899 * fre1;
          data_out[5] = 85.899 * fre2;
          wave1 = 1;
          wave2 = 1;
          SPI_1(&wave1,&wave2);
//          printf("fre1=%lf,fre2=%lf\r\n",fre1,fre2);
      }
      else {
          HAL_GPIO_WritePin(GPIOH,GPIO_PIN_5,0);
          HAL_GPIO_WritePin(GPIOA,GPIO_PIN_5,1);
          HAL_GPIO_WritePin(GPIOH,GPIO_PIN_4,0);
      }
    /* USER CODE END WHILE */

  }
}

void SystemClock_Config(void)
{
  RCC_OscInitTypeDef RCC_OscInitStruct = {0};
  RCC_ClkInitTypeDef RCC_ClkInitStruct = {0};

  /** Supply configuration update enable
  */
  HAL_PWREx_ConfigSupply(PWR_LDO_SUPPLY);
  /** Configure the main internal regulator output voltage
  */
  __HAL_PWR_VOLTAGESCALING_CONFIG(PWR_REGULATOR_VOLTAGE_SCALE0);

  while(!__HAL_PWR_GET_FLAG(PWR_FLAG_VOSRDY)) {}
  /** Macro to configure the PLL clock source
  */
  __HAL_RCC_PLL_PLLSOURCE_CONFIG(RCC_PLLSOURCE_HSE);
  /** Initializes the RCC Oscillators according to the specified parameters
  * in the RCC_OscInitTypeDef structure.
  */
  RCC_OscInitStruct.OscillatorType = RCC_OSCILLATORTYPE_HSE;
  RCC_OscInitStruct.HSEState = RCC_HSE_ON;
  RCC_OscInitStruct.PLL.PLLState = RCC_PLL_ON;
  RCC_OscInitStruct.PLL.PLLSource = RCC_PLLSOURCE_HSE;
  RCC_OscInitStruct.PLL.PLLM = 5;
  RCC_OscInitStruct.PLL.PLLN = 192;
  RCC_OscInitStruct.PLL.PLLP = 2;
  RCC_OscInitStruct.PLL.PLLQ = 2;
  RCC_OscInitStruct.PLL.PLLR = 2;
  RCC_OscInitStruct.PLL.PLLRGE = RCC_PLL1VCIRANGE_2;
  RCC_OscInitStruct.PLL.PLLVCOSEL = RCC_PLL1VCOWIDE;
  RCC_OscInitStruct.PLL.PLLFRACN = 0;
  if (HAL_RCC_OscConfig(&RCC_OscInitStruct) != HAL_OK)
  {
    Error_Handler();
  }
  /** Initializes the CPU, AHB and APB buses clocks
  */
  RCC_ClkInitStruct.ClockType = RCC_CLOCKTYPE_HCLK|RCC_CLOCKTYPE_SYSCLK
                              |RCC_CLOCKTYPE_PCLK1|RCC_CLOCKTYPE_PCLK2
                              |RCC_CLOCKTYPE_D3PCLK1|RCC_CLOCKTYPE_D1PCLK1;
  RCC_ClkInitStruct.SYSCLKSource = RCC_SYSCLKSOURCE_PLLCLK;
  RCC_ClkInitStruct.SYSCLKDivider = RCC_SYSCLK_DIV1;
  RCC_ClkInitStruct.AHBCLKDivider = RCC_HCLK_DIV2;
  RCC_ClkInitStruct.APB3CLKDivider = RCC_APB3_DIV2;
  RCC_ClkInitStruct.APB1CLKDivider = RCC_APB1_DIV2;
  RCC_ClkInitStruct.APB2CLKDivider = RCC_APB2_DIV2;
  RCC_ClkInitStruct.APB4CLKDivider = RCC_APB4_DIV2;

  if (HAL_RCC_ClockConfig(&RCC_ClkInitStruct, FLASH_LATENCY_4) != HAL_OK)
  {
    Error_Handler();
  }
}

void PeriphCommonClock_Config(void)
{
  RCC_PeriphCLKInitTypeDef PeriphClkInitStruct = {0};

  /** Initializes the peripherals clock
  */
  PeriphClkInitStruct.PeriphClockSelection = RCC_PERIPHCLK_ADC|RCC_PERIPHCLK_SPI2;
  PeriphClkInitStruct.PLL2.PLL2M = 2;
  PeriphClkInitStruct.PLL2.PLL2N = 12;
  PeriphClkInitStruct.PLL2.PLL2P = 3;
  PeriphClkInitStruct.PLL2.PLL2Q = 2;
  PeriphClkInitStruct.PLL2.PLL2R = 2;
  PeriphClkInitStruct.PLL2.PLL2RGE = RCC_PLL2VCIRANGE_3;
  PeriphClkInitStruct.PLL2.PLL2VCOSEL = RCC_PLL2VCOMEDIUM;
  PeriphClkInitStruct.PLL2.PLL2FRACN = 0;
  PeriphClkInitStruct.Spi123ClockSelection = RCC_SPI123CLKSOURCE_PLL2;
  PeriphClkInitStruct.AdcClockSelection = RCC_ADCCLKSOURCE_PLL2;
  if (HAL_RCCEx_PeriphCLKConfig(&PeriphClkInitStruct) != HAL_OK)
  {
    Error_Handler();
  }
}

void Error_Handler(void)
{
  __disable_irq();
  while (1)
  {
  }
}

/************************ (C) COPYRIGHT STMicroelectronics *****END OF FILE****/
